# CH32M030 register map
Vendor: WCH Ltd.; File version: 1.1
Registers are 32-bit, read-write, reset 0x0 unless marked. A register's access mark holds for its fields unless they carry their own. Offsets are from the block's base; [hi:lo] are bit positions; lines under a group give offsets from that group; {n}, {i} and the like mark numbered series.

## ADC1 — Analog to digital converter
Base 0x40012400
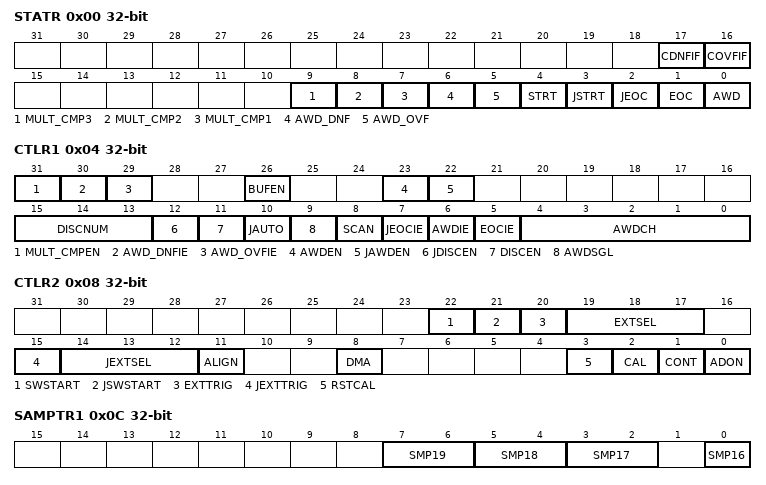
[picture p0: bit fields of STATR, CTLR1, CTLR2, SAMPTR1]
0x00 STATR — ADC status register
  [17] CDNFIF — clear the conversion value underflow interrupt flag bit
  [16] COVFIF — clear the conversion value overflow interrupt flag bit
  [9] MULT_CMP3 — result of multi-threshold comparison 3
  [8] MULT_CMP2 — result of multi-threshold comparison 2
  [7] MULT_CMP1 — result of multi-threshold comparison 1
  [6] AWD_DNF — analog watchdog underflow flag
  [5] AWD_OVF — analog watchdog overflow flag
  [4] STRT — Regular channel start flag
  [3] JSTRT — Injected channel start flag
  [2] JEOC — Injected channel end of conversion
  [1] EOC — Regular channel end of conversion
  [0] AWD — Analog watchdog flag
0x04 CTLR1 — control register 1/TKEY_V_CTLR
  [31] MULT_CMPEN — multi-threshold comparison function enabled
  [30] AWD_DNFIE — analog watchdog underflow interrupt enable
  [29] AWD_OVFIE — analog watchdog overflow interrupt enable
  [26] BUFEN — Buffer enabled by the ADC
  [23] AWDEN — Analog watchdog enable on regular channels
  [22] JAWDEN — Analog watchdog enable on injected channels
  [15:13] DISCNUM — Discontinuous mode channel count
  [12] JDISCEN — Discontinuous mode on injected channels
  [11] DISCEN — Discontinuous mode on regular channels
  [10] JAUTO — Automatic injected group conversion
  [9] AWDSGL — Enable the watchdog on a single channel in scan mode
  [8] SCAN — Scan mode enable
  [7] JEOCIE — Interrupt enable for injected channels
  [6] AWDIE — Analog watchdog interrupt enable
  [5] EOCIE — Interrupt enable for EOC
  [4:0] AWDCH — Analog watchdog channel select bits
0x08 CTLR2 — control register 2
  [22] SWSTART — Start conversion of regular channels
  [21] JSWSTART — Start conversion of injected channels
  [20] EXTTRIG — External trigger conversion mode for regular channels
  [19:17] EXTSEL — External event select for regular group
  [15] JEXTTRIG — External trigger conversion mode for injected channels
  [14:12] JEXTSEL — External event select for injected group
  [11] ALIGN — Data alignment
  [8] DMA — Direct memory access mode
  [3] RSTCAL — Reset calibration
  [2] CAL — A/D calibration
  [1] CONT — Continuous conversion
  [0] ADON — A/D converter ON/OFF
0x0C SAMPTR1 — sample time register 1
  [7:6] SMP19 — Channel 19 sample time selection
  [5:4] SMP18 — Channel 18 sample time selection
  [3:2] SMP17 — Channel 17 sample time selection
  [0] SMP16 — Channel 16 sample time selection
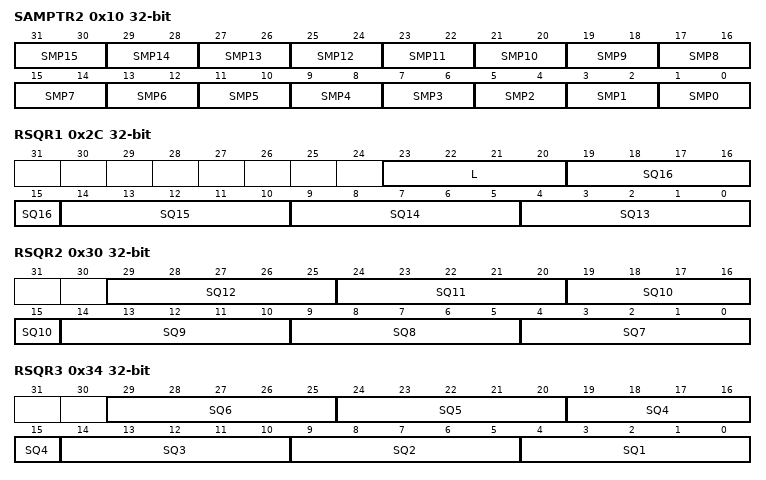
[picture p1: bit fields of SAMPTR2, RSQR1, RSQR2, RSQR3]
0x10 SAMPTR2 — sample time register 2
  [2n+1:2n] SMP{n} (n=0..15) — Channel {n} sample time selection
{0x10+4i} IOFR{i} (i=1..4) — injected channel data offset register x
  [11:0] JOFFSET{i} — Data offset for injected channel x
0x24 WDHTR reset 0xFFF — watchdog higher threshold register
  [11:0] HT — Analog watchdog higher threshold
0x28 WDLTR — watchdog lower threshold register
  [11:0] LT — Analog watchdog lower threshold
0x2C RSQR1 — regular sequence register 1
  [23:20] L — Regular channel sequence length
  [5n-61:5n-65] SQ{n} (n=13..16) — {n}th conversion in regular sequence
0x30 RSQR2 — regular sequence register 2
  [5n-31:5n-35] SQ{n} (n=7..12) — {n}th conversion in regular sequence
0x34 RSQR3 — regular sequence register 3
  [29:25] SQ6 — 6th conversion in regular sequence
  [24:20] SQ5 — 5th conversion in regular sequence
  [19:15] SQ4 — 4th conversion in regular sequence
  [14:10] SQ3 — 3rd conversion in regular sequence
  [9:5] SQ2 — 2nd conversion in regular sequence
  [4:0] SQ1 — 1st conversion in regular sequence
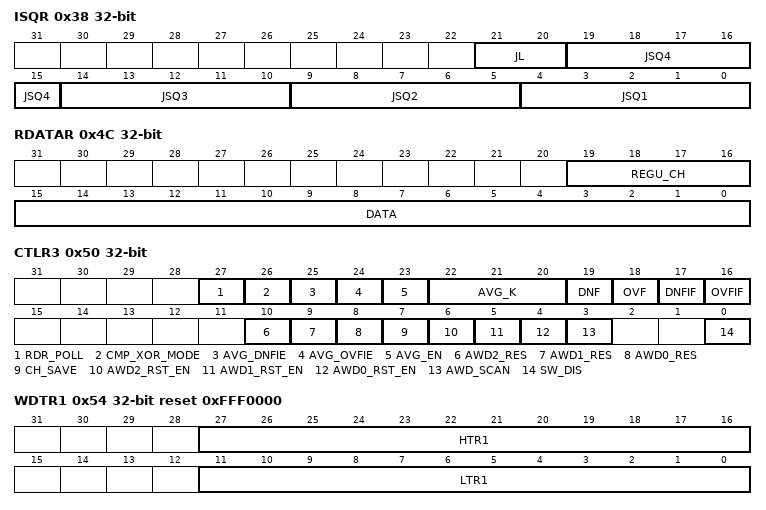
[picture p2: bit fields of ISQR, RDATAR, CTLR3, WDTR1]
0x38 ISQR — injected sequence register
  [21:20] JL — Injected sequence length
  [19:15] JSQ4 — 4th conversion in injected sequence
  [14:10] JSQ3 — 3rd conversion in injected sequence
  [9:5] JSQ2 — 2nd conversion in injected sequence
  [4:0] JSQ1 — 1st conversion in injected sequence
{0x38+4i} IDATAR{i} ro (i=1..4) — injected data register {i}
  [15:0] JDATA — Injected data
0x4C RDATAR ro — regular data register
  [19:16] REGU_CH — Channel order indication
  [15:0] DATA — Regular data
0x50 CTLR3 — ADC Control register 3
  [27] RDR_POLL — The polling saving function of the rule channel data was enabled
  [26] CMP_XOR_MODE — comparison result the OXR mode is enabled
  [25] AVG_DNFIE — Conversion value underflow interrupt enable
  [24] AVG_OVFIE — Conversion value overflow interrupt enable
  [23] AVG_EN — The moving average function was enabled
  [22:20] AVG_K — Sliding average window value setting
  [19] DNF — Conversion value underflow flag bit
  [18] OVF — Conversion value overflow flag bit
  [17] DNFIF — Conversion value underflow interrupt flag bit
  [16] OVFIF — Conversion value overflow interrupt flag bit
  [10] AWD2_RES — Analog Watchdog 2 compares the results
  [9] AWD1_RES — Analog Watchdog 1 compares the results
  [8] AWD0_RES — Analog Watchdog 0 compares the results
  [7] CH_SAVE — Rule data channel indicates function enable bit
  [6] AWD2_RST_EN — Analog Watchdog 2 reset enable bit
  [5] AWD1_RST_EN — Analog Watchdog 1 reset enable bit
  [4] AWD0_RST_EN — Analog Watchdog 0 reset enable bit
  [3] AWD_SCAN — Analog Watchdog sans the enable
  [0] SW_DIS — ADC channel switchover function in advance was enabled
0x54 WDTR1 reset 0xFFF0000 — ADC watchdog 1 threshold register
  [27:16] HTR1 — Analog watchdog higher threshold setting value
  [11:0] LTR1 — Analog watchdog lower threshold setting value
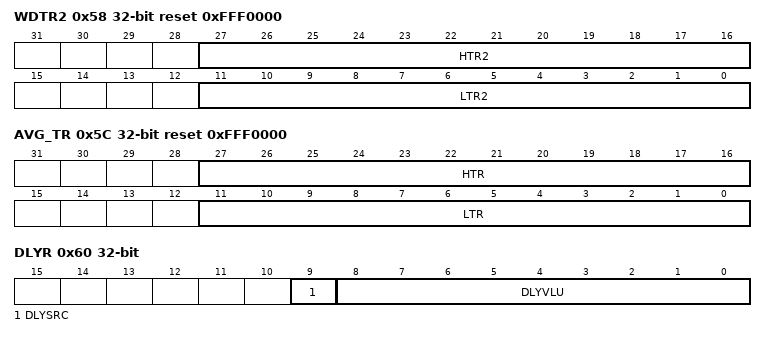
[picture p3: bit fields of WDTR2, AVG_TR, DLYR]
0x58 WDTR2 reset 0xFFF0000 — ADC watchdog 2 threshold register
  [27:16] HTR2 — Analog watchdog higher threshold setting value
  [11:0] LTR2 — Analog watchdog lower threshold setting value
0x5C AVG_TR reset 0xFFF0000 — ADC average threshold register
  [27:16] HTR — higher average threshold setting value
  [11:0] LTR — lower average threshold setting value
0x60 DLYR — delay data register
  [9] DLYSRC — External trigger source delay selection
  [8:0] DLYVLU — External trigger data delay time configuration
0x64 AVG_DR ro — ADC average data register
  [11:0] AVG_DR — ADC moving average
{0x60+4i} RDATAR{i} ro (i=2..4) — regular data register {i}
  [11:0] DATA — Regular data
